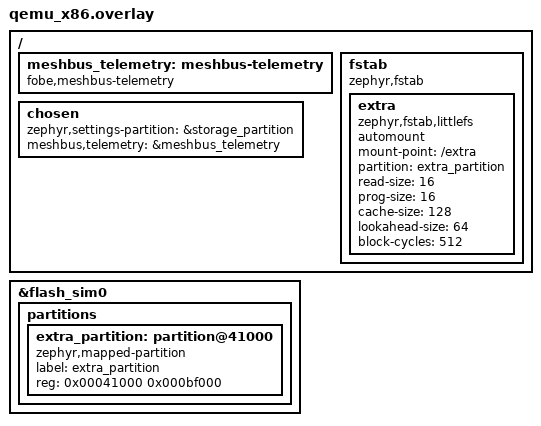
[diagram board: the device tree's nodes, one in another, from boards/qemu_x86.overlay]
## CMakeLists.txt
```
cmake_minimum_required(VERSION 3.20.0)

find_package(Zephyr REQUIRED HINTS $ENV{ZEPHYR_BASE})
project(meshbus_llext_contract_test)

target_sources(app PRIVATE src/test_api.c)

set(llext_targets)
set(llext_outputs)


set(ext_app_bin ${PROJECT_BINARY_DIR}/llext/mb_app.mba)
set(ext_app_inc ${ZEPHYR_BINARY_DIR}/include/generated/mb_app.inc)
set(ext_other_edk_app_bin ${PROJECT_BINARY_DIR}/llext/mb_otheredk.mba)
set(ext_other_edk_app_inc ${ZEPHYR_BINARY_DIR}/include/generated/mb_otheredk_app.inc)
set(ext_older_edk_app_bin ${PROJECT_BINARY_DIR}/llext/mb_olderedk.mba)
set(ext_older_edk_app_inc ${ZEPHYR_BINARY_DIR}/include/generated/mb_olderedk_app.inc)
set(ext_bad_target_app_bin ${PROJECT_BINARY_DIR}/llext/mb_badtargetapp.mba)
set(ext_bad_target_app_inc ${ZEPHYR_BINARY_DIR}/include/generated/mb_badtarget_app.inc)
set(ext_old_meta_app_bin ${PROJECT_BINARY_DIR}/llext/mb_oldmeta.mba)
set(ext_old_meta_app_inc ${ZEPHYR_BINARY_DIR}/include/generated/mb_oldmeta_app.inc)
set(ext_bad_reserved_app_bin ${PROJECT_BINARY_DIR}/llext/mb_badreserved.mba)
set(ext_bad_reserved_app_inc ${ZEPHYR_BINARY_DIR}/include/generated/mb_badreserved_app.inc)
set(ext_big_app_bin ${PROJECT_BINARY_DIR}/llext/mb_bigapp.mba)
set(ext_big_app_inc ${ZEPHYR_BINARY_DIR}/include/generated/mb_bigapp.inc)
set(ext_bad_icon_app_bin ${PROJECT_BINARY_DIR}/llext/mb_badicon.mba)
set(ext_bad_icon_app_inc ${ZEPHYR_BINARY_DIR}/include/generated/mb_badicon.inc)
set(ext_bad_symbol_app_bin ${PROJECT_BINARY_DIR}/llext/mb_badsymapp.mba)
set(ext_bad_symbol_app_inc ${ZEPHYR_BINARY_DIR}/include/generated/mb_badsymapp.inc)

set(MESHBUS_LLEXT_REUSE_APP "" CACHE FILEPATH
	"Existing compatible app package to embed instead of rebuilding mb_app")
if(MESHBUS_LLEXT_REUSE_APP)
	get_filename_component(ext_app_bin "${MESHBUS_LLEXT_REUSE_APP}"
		ABSOLUTE BASE_DIR "${CMAKE_BINARY_DIR}")
	if(NOT EXISTS "${ext_app_bin}")
		message(FATAL_ERROR "Reused LLEXT app does not exist: ${ext_app_bin}")
	endif()
else()
	add_llext_target(mb_app_ext
		OUTPUT ${ext_app_bin}
		SOURCES ${CMAKE_CURRENT_SOURCE_DIR}/src/app_ext.c
	)
	list(APPEND llext_targets mb_app_ext)
	list(APPEND llext_outputs ${ext_app_bin})
endif()
add_llext_target(mb_otheredk_app_ext
	OUTPUT ${ext_other_edk_app_bin}
	SOURCES ${CMAKE_CURRENT_SOURCE_DIR}/src/app_other_edk_ext.c
)
add_llext_target(mb_olderedk_app_ext
	OUTPUT ${ext_older_edk_app_bin}
	SOURCES ${CMAKE_CURRENT_SOURCE_DIR}/src/app_older_edk_ext.c
)
add_llext_target(mb_badtarget_app_ext
	OUTPUT ${ext_bad_target_app_bin}
	SOURCES ${CMAKE_CURRENT_SOURCE_DIR}/src/app_bad_target_ext.c
)
add_llext_target(mb_oldmeta_app_ext
	OUTPUT ${ext_old_meta_app_bin}
	SOURCES ${CMAKE_CURRENT_SOURCE_DIR}/src/app_old_metadata_ext.c
)
add_llext_target(mb_badreserved_app_ext
	OUTPUT ${ext_bad_reserved_app_bin}
	SOURCES ${CMAKE_CURRENT_SOURCE_DIR}/src/app_bad_reserved_ext.c
)
add_llext_target(mb_bigapp_ext
	OUTPUT ${ext_big_app_bin}
	SOURCES ${CMAKE_CURRENT_SOURCE_DIR}/src/app_big_heap_ext.c
)
add_llext_target(mb_badicon_ext
	OUTPUT ${ext_bad_icon_app_bin}
	SOURCES ${CMAKE_CURRENT_SOURCE_DIR}/src/app_bad_icon_ext.c
)
add_llext_target(mb_badsymapp_ext
	OUTPUT ${ext_bad_symbol_app_bin}
	SOURCES ${CMAKE_CURRENT_SOURCE_DIR}/src/app_bad_symbol_ext.c
)

list(APPEND llext_targets
	mb_otheredk_app_ext
	mb_olderedk_app_ext
	mb_badtarget_app_ext
	mb_oldmeta_app_ext
	mb_badreserved_app_ext
	mb_bigapp_ext
	mb_badicon_ext
	mb_badsymapp_ext
)
list(APPEND llext_outputs
	${ext_other_edk_app_bin}
	${ext_older_edk_app_bin}
	${ext_bad_target_app_bin}
	${ext_old_meta_app_bin}
	${ext_bad_reserved_app_bin}
	${ext_big_app_bin}
	${ext_bad_icon_app_bin}
	${ext_bad_symbol_app_bin}
)

generate_inc_file_for_target(app ${ext_app_bin} ${ext_app_inc})
generate_inc_file_for_target(app ${ext_other_edk_app_bin} ${ext_other_edk_app_inc})
generate_inc_file_for_target(app ${ext_older_edk_app_bin} ${ext_older_edk_app_inc})
generate_inc_file_for_target(app ${ext_bad_target_app_bin} ${ext_bad_target_app_inc})
generate_inc_file_for_target(app ${ext_old_meta_app_bin} ${ext_old_meta_app_inc})
generate_inc_file_for_target(app ${ext_bad_reserved_app_bin} ${ext_bad_reserved_app_inc})
generate_inc_file_for_target(app ${ext_big_app_bin} ${ext_big_app_inc})
generate_inc_file_for_target(app ${ext_bad_icon_app_bin} ${ext_bad_icon_app_inc})
generate_inc_file_for_target(app ${ext_bad_symbol_app_bin} ${ext_bad_symbol_app_inc})

foreach(llext_target ${llext_targets})
	if(TARGET ${llext_target}_llext_lib AND TARGET meshbus_proto)
		add_dependencies(${llext_target}_llext_lib meshbus_proto)
	endif()
endforeach()

foreach(ext ${llext_outputs})
	add_custom_command(
		OUTPUT ${ext}
		APPEND
		COMMAND ${CMAKE_OBJCOPY}
			--set-section-flags
			.meshbus.llext.meta=contents,readonly
			${ext}
	)
endforeach()
```

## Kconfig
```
mainmenu "Meshbus LLEXT contract tests"

source "Kconfig.zephyr"

config MESHBUS_LLEXT_TEST_ADD_SYSTEM_HEAP
	bool "Add the test-only LLEXT system heap requirement"
	default n

config HEAP_MEM_POOL_ADD_SIZE_MESHBUS_LLEXT_TEST
	int
	default 196608 if MESHBUS_LLEXT_TEST_ADD_SYSTEM_HEAP
	default 0
	help
	  Test-only subsystem heap requirement used to verify that LLEXT admission
	  follows Zephyr's final K_HEAP_MEM_POOL_SIZE rather than only the base
	  CONFIG_HEAP_MEM_POOL_SIZE.
```

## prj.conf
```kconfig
CONFIG_ZTEST=y
CONFIG_ASSERT=y
CONFIG_LOG=y

CONFIG_MESHBUS=y
CONFIG_MESHBUS_SHELL=y
CONFIG_MESHBUS_LLEXT=y
CONFIG_MESHBUS_LLEXT_SHELL=y
CONFIG_MESHBUS_LLEXT_DEFAULT_ENABLED=y
CONFIG_MESHBUS_LLEXT_DYNAMIC_HEAP_MARGIN_PERCENT=5
CONFIG_MESHBUS_SETTINGS_PERSISTENCE_DELAY=50

CONFIG_LLEXT=y
CONFIG_LLEXT_HEAP_DYNAMIC=y
CONFIG_LLEXT_SHELL=n
CONFIG_ZBUS_PRIORITY_BOOST=n
CONFIG_ZBUS_RUNTIME_OBSERVERS=y

CONFIG_FILE_SYSTEM=y
CONFIG_FILE_SYSTEM_LITTLEFS=y
CONFIG_FS_LITTLEFS_FMP_DEV=y
CONFIG_FLASH=y
CONFIG_FLASH_MAP=y
CONFIG_FLASH_SIMULATOR=y

CONFIG_SETTINGS=y
CONFIG_SETTINGS_ZMS=y
CONFIG_SETTINGS_ZMS_LL_CACHE=y
CONFIG_SETTINGS_ZMS_LL_CACHE_SIZE=512
CONFIG_ZMS=y
CONFIG_ZMS_LOOKUP_CACHE=y
CONFIG_ZMS_LOOKUP_CACHE_SIZE=512
CONFIG_ZMS_LOOKUP_CACHE_FOR_SETTINGS=y

CONFIG_SHELL=y
CONFIG_SHELL_BACKEND_DUMMY=y
CONFIG_SHELL_BACKEND_SERIAL=n

CONFIG_MAIN_STACK_SIZE=4096
CONFIG_SYSTEM_WORKQUEUE_STACK_SIZE=4096
CONFIG_ZTEST_STACK_SIZE=4096
CONFIG_HEAP_MEM_POOL_SIZE=196608
CONFIG_THREAD_STACK_INFO=y

# Application service bridges
CONFIG_SENSOR=y
CONFIG_MESHBUS_TELEMETRY=y
CONFIG_MESHBUS_TELEMETRY_DEFAULT_ENABLED=n
CONFIG_MESHBUS_TELEMETRY_SHELL=n
CONFIG_MESHBUS_TELEMETRY_STATS=n
CONFIG_MESHBUS_NOTIFY=y
CONFIG_MESHBUS_NOTIFY_SHELL=n
CONFIG_INPUT=y
CONFIG_MESHBUS_INPUT=y
CONFIG_MESHBUS_INPUT_SHELL=n
```

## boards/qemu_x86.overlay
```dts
&flash_sim0 {
	partitions {
		extra_partition: partition@41000 {
			compatible = "zephyr,mapped-partition";
			label = "extra_partition";
			reg = <0x00041000 0x000bf000>;
		};
	};
};

/ {
	meshbus_telemetry: meshbus-telemetry {
		compatible = "fobe,meshbus-telemetry";
	};

	fstab: fstab {
		compatible = "zephyr,fstab";
		extra: extra {
			compatible = "zephyr,fstab,littlefs";
			automount;
			mount-point = "/extra";
			partition = <&extra_partition>;
			read-size = <16>;
			prog-size = <16>;
			cache-size = <128>;
			lookahead-size = <64>;
			block-cycles = <512>;
		};
	};

	chosen {
		zephyr,settings-partition = &storage_partition;
		meshbus,telemetry = &meshbus_telemetry;
	};
};
```

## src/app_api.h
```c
/* SPDX-License-Identifier: Apache-2.0 */

#ifndef MESHBUS_LLEXT_TEST_APP_API_H_
#define MESHBUS_LLEXT_TEST_APP_API_H_

#define MB_LLEXT_TEST_EVT_APP 3

int mb_llext_test_hook(int event);

#endif /* MESHBUS_LLEXT_TEST_APP_API_H_ */
```

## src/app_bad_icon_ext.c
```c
// SPDX-License-Identifier: Apache-2.0

#include <zephyr/kernel.h>
#include <zephyr/llext/symbol.h>
#include <zephyr/meshbus/llext.h>

static const struct meshbus_llext_app_metadata app_metadata
	MESHBUS_LLEXT_APP_METADATA_ATTR = {
		.magic = MESHBUS_LLEXT_APP_METADATA_MAGIC,
		.metadata_version = MESHBUS_LLEXT_APP_METADATA_VERSION,
		.size = sizeof(struct meshbus_llext_app_metadata),
		.stack_size = 1024U,
		.heap_size = 16384U,
		.icon_data_size = 1U,
		.id = "mb_badicon",
		.name = "Bad Icon App",
		.app_version = "1.0.0",
		.entry_point_symbol = "app_bad_icon_entry",
		.edk_version = "0.1.0",
		.target = CONFIG_BOARD_TARGET,
		.icon_data = {0xff},
	};

void app_bad_icon_entry(void *args)
{
	ARG_UNUSED(args);
}
EXPORT_SYMBOL(app_bad_icon_entry);
```

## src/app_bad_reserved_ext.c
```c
// SPDX-License-Identifier: Apache-2.0

#include <zephyr/kernel.h>
#include <zephyr/llext/symbol.h>
#include <zephyr/meshbus/llext.h>

static const struct meshbus_llext_app_metadata app_metadata
	MESHBUS_LLEXT_APP_METADATA_ATTR = {
		.magic = MESHBUS_LLEXT_APP_METADATA_MAGIC,
		.metadata_version = MESHBUS_LLEXT_APP_METADATA_VERSION,
		.size = sizeof(struct meshbus_llext_app_metadata),
		.stack_size = 1024U,
		.heap_size = 16384U,
		.id = "mb_badreserved",
		.name = "Bad Reserved App",
		.app_version = "1.0.0",
		.entry_point_symbol = "app_bad_reserved_entry",
		.edk_version = "0.1.0",
		.compatibility_reserved = {1U},
		.target = CONFIG_BOARD_TARGET,
	};

void app_bad_reserved_entry(void *args)
{
	ARG_UNUSED(args);
}
EXPORT_SYMBOL(app_bad_reserved_entry);
```

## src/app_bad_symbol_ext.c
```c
// SPDX-License-Identifier: Apache-2.0

#include <zephyr/meshbus/llext.h>
#include <zephyr/llext/symbol.h>

static const struct meshbus_llext_app_metadata app_metadata
	MESHBUS_LLEXT_APP_METADATA_ATTR = {
		.magic = MESHBUS_LLEXT_APP_METADATA_MAGIC,
		.metadata_version = MESHBUS_LLEXT_APP_METADATA_VERSION,
		.size = sizeof(struct meshbus_llext_app_metadata),
		.stack_size = 1024U,
		.heap_size = 32768U,
		.icon_data_size = 0U,
		.id = "mb_badsymapp",
		.name = "Missing Symbol App",
		.app_version = "1.0.0",
		.entry_point_symbol = "missing_app_entry",
		.edk_version = "0.1.0",
		.target = CONFIG_BOARD_TARGET,
	};

void present_app_symbol(void)
{
}
EXPORT_SYMBOL(present_app_symbol);
```

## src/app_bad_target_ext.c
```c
// SPDX-License-Identifier: Apache-2.0

#include <zephyr/kernel.h>
#include <zephyr/llext/symbol.h>
#include <zephyr/meshbus/llext.h>

static const struct meshbus_llext_app_metadata app_metadata
	MESHBUS_LLEXT_APP_METADATA_ATTR = {
		.magic = MESHBUS_LLEXT_APP_METADATA_MAGIC,
		.metadata_version = MESHBUS_LLEXT_APP_METADATA_VERSION,
		.size = sizeof(struct meshbus_llext_app_metadata),
		.stack_size = 1024U,
		.heap_size = 16384U,
		.id = "mb_badtargetapp",
		.name = "Bad Target App",
		.app_version = "1.0.0",
		.entry_point_symbol = "app_bad_target_entry",
		.edk_version = "0.1.0",
		.target = "other/target",
	};

void app_bad_target_entry(void *args)
{
	ARG_UNUSED(args);
}
EXPORT_SYMBOL(app_bad_target_entry);
```

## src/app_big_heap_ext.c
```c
// SPDX-License-Identifier: Apache-2.0

#include <zephyr/kernel.h>
#include <zephyr/llext/symbol.h>
#include <zephyr/meshbus/llext.h>

static const struct meshbus_llext_app_metadata app_metadata
	MESHBUS_LLEXT_APP_METADATA_ATTR = {
		.magic = MESHBUS_LLEXT_APP_METADATA_MAGIC,
		.metadata_version = MESHBUS_LLEXT_APP_METADATA_VERSION,
		.size = sizeof(struct meshbus_llext_app_metadata),
		.stack_size = 1024U,
		.heap_size = CONFIG_MESHBUS_LLEXT_APP_HEAP_RESERVE_SIZE + 1U,
		.icon_data_size = 0U,
		.id = "mb_bigapp",
		.name = "Big App",
		.app_version = "1.0.0",
		.entry_point_symbol = "app_big_heap_entry",
		.edk_version = "0.1.0",
		.target = CONFIG_BOARD_TARGET,
	};

void app_big_heap_entry(void *args)
{
	ARG_UNUSED(args);
}
EXPORT_SYMBOL(app_big_heap_entry);
```

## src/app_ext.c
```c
// SPDX-License-Identifier: Apache-2.0
/*
 * Copyright (c) 2026 FoBE Studio
 */

#include <zephyr/kernel.h>
#include <zephyr/llext/symbol.h>
#include <zephyr/meshbus/llext.h>

#include "app_api.h"

static const struct meshbus_llext_app_metadata app_metadata
	MESHBUS_LLEXT_APP_METADATA_ATTR = {
		.magic = MESHBUS_LLEXT_APP_METADATA_MAGIC,
			.metadata_version = MESHBUS_LLEXT_APP_METADATA_VERSION,
			.size = sizeof(struct meshbus_llext_app_metadata),
			.stack_size = 1024U,
			.heap_size = 32768U,
			.icon_data_size = MESHBUS_LLEXT_APP_ICON_DATA_SIZE,
			.id = "mb_app",
			.name = "Meshbus App",
			.app_version = "1.0.0",
			.entry_point_symbol = "app_test_entry",
			.edk_version = "0.1.0",
			.target = CONFIG_BOARD_TARGET,
			.icon_data = {
				0x00, 0x03, 0x7c, 0x02, 0x44, 0x02, 0x44, 0x02, 0x7c, 0x02,
				0x44, 0x02, 0x44, 0x02, 0x44, 0x02, 0x7c, 0x02, 0x00, 0x00,
			},
		};

void app_test_entry(void *args)
{
	ARG_UNUSED(args);

	(void)mb_llext_test_hook(MB_LLEXT_TEST_EVT_APP);
}
EXPORT_SYMBOL(app_test_entry);
```

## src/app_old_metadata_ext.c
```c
// SPDX-License-Identifier: Apache-2.0

#include <zephyr/kernel.h>
#include <zephyr/llext/symbol.h>
#include <zephyr/meshbus/llext.h>

static const struct meshbus_llext_app_metadata app_metadata
	MESHBUS_LLEXT_APP_METADATA_ATTR = {
		.magic = MESHBUS_LLEXT_APP_METADATA_MAGIC,
		.metadata_version = MESHBUS_LLEXT_APP_METADATA_VERSION + 1U,
		.size = sizeof(struct meshbus_llext_app_metadata),
		.stack_size = 1024U,
		.heap_size = 16384U,
		.id = "mb_oldmeta",
		.name = "Old Metadata App",
		.app_version = "1.0.0",
		.entry_point_symbol = "app_old_metadata_entry",
		.edk_version = "0.1.0",
		.target = CONFIG_BOARD_TARGET,
	};

void app_old_metadata_entry(void *args)
{
	ARG_UNUSED(args);
}
EXPORT_SYMBOL(app_old_metadata_entry);
```

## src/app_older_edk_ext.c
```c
// SPDX-License-Identifier: Apache-2.0

#include <zephyr/kernel.h>
#include <zephyr/llext/symbol.h>
#include <zephyr/meshbus/llext.h>

static const struct meshbus_llext_app_metadata app_metadata
	MESHBUS_LLEXT_APP_METADATA_ATTR = {
		.magic = MESHBUS_LLEXT_APP_METADATA_MAGIC,
		.metadata_version = MESHBUS_LLEXT_APP_METADATA_VERSION,
		.size = sizeof(struct meshbus_llext_app_metadata),
		.stack_size = 1024U,
		.heap_size = 16384U,
		.id = "mb_olderedk",
		.name = "Older EDK",
		.app_version = "1.0.0",
		.entry_point_symbol = "app_older_edk_entry",
		.edk_version = "0.0.1",
		.target = CONFIG_BOARD_TARGET,
	};

void app_older_edk_entry(void *args)
{
	ARG_UNUSED(args);
}
EXPORT_SYMBOL(app_older_edk_entry);
```

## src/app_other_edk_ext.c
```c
// SPDX-License-Identifier: Apache-2.0

#include <zephyr/kernel.h>
#include <zephyr/llext/symbol.h>
#include <zephyr/meshbus/llext.h>

static const struct meshbus_llext_app_metadata app_metadata
	MESHBUS_LLEXT_APP_METADATA_ATTR = {
		.magic = MESHBUS_LLEXT_APP_METADATA_MAGIC,
		.metadata_version = MESHBUS_LLEXT_APP_METADATA_VERSION,
		.size = sizeof(struct meshbus_llext_app_metadata),
		.stack_size = 1024U,
		.heap_size = 16384U,
		.id = "mb_otheredk",
		.name = "Different EDK",
		.app_version = "1.0.0",
		.entry_point_symbol = "app_other_edk_entry",
		.edk_version = "9.0.0",
		.target = CONFIG_BOARD_TARGET,
	};

void app_other_edk_entry(void *args)
{
	ARG_UNUSED(args);
}
EXPORT_SYMBOL(app_other_edk_entry);
```

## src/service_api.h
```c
/* SPDX-License-Identifier: Apache-2.0 */

#ifndef MESHBUS_LLEXT_TEST_SERVICE_API_H_
#define MESHBUS_LLEXT_TEST_SERVICE_API_H_

#define MB_LLEXT_TEST_EVT_SETUP 1
#define MB_LLEXT_TEST_EVT_EXIT 2
#define MB_LLEXT_TEST_EVT_APP 3

int mb_llext_test_hook(int event);

#endif /* MESHBUS_LLEXT_TEST_SERVICE_API_H_ */
```

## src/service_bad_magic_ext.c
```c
// SPDX-License-Identifier: Apache-2.0

#include <zephyr/kernel.h>
#include <zephyr/llext/symbol.h>
#include <zephyr/meshbus/llext.h>

static const struct meshbus_llext_service_metadata service_metadata
	MESHBUS_LLEXT_SERVICE_METADATA_ATTR = {
		.magic = MESHBUS_LLEXT_SERVICE_METADATA_MAGIC + 1U,
		.metadata_version = MESHBUS_LLEXT_SERVICE_METADATA_VERSION,
		.size = sizeof(struct meshbus_llext_service_metadata),
		.thread_stack_size = 1024U,
		.heap_size = 16384U,
		.id = "mb_badmagic",
		.name = "Bad Magic",
		.service_version = "1.0.0",
		.entry_point_symbol = "service_bad_magic_entry",
		.edk_version = "0.1.0",
		.target = CONFIG_BOARD_TARGET,
	};

void service_bad_magic_entry(void *p1, void *p2, void *p3)
{
	ARG_UNUSED(p1);
	ARG_UNUSED(p2);
	ARG_UNUSED(p3);
}
EXPORT_SYMBOL(service_bad_magic_entry);
```
